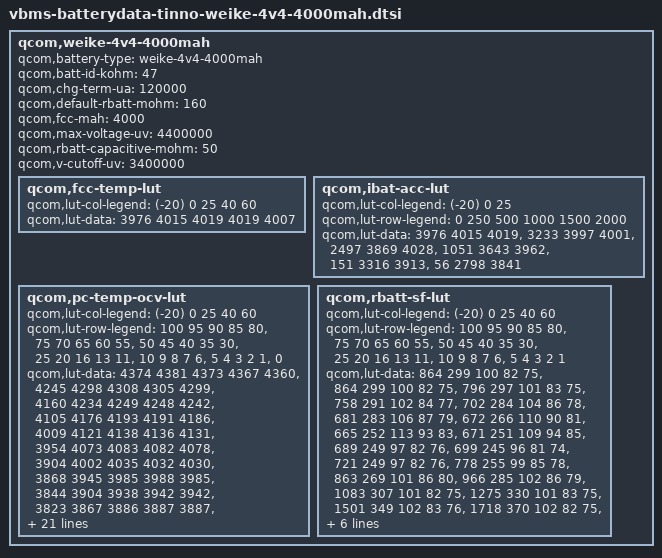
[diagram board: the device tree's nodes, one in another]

qcom,weike-4v4-4000mah {
	qcom,battery-type = "weike-4v4-4000mah";
	qcom,batt-id-kohm = <47>;
	qcom,chg-term-ua = <120000>;
	qcom,default-rbatt-mohm = <160>;
	qcom,fcc-mah = <4000>;
	qcom,max-voltage-uv = <4400000>;
	qcom,rbatt-capacitive-mohm = <50>;
	qcom,v-cutoff-uv = <3400000>;

	qcom,fcc-temp-lut {
		qcom,lut-col-legend = <(-20) 0 25 40 60>;
		qcom,lut-data = <3976 4015 4019 4019 4007>;
	};

	qcom,ibat-acc-lut {
		qcom,lut-col-legend = <(-20) 0 25>;
		qcom,lut-row-legend = <0 250 500 1000 1500 2000>;
		qcom,lut-data = <3976 4015 4019>,
				<3233 3997 4001>,
				<2497 3869 4028>,
				<1051 3643 3962>,
				<151 3316 3913>,
				<56 2798 3841>;
	};

	qcom,pc-temp-ocv-lut {
		qcom,lut-col-legend = <(-20) 0 25 40 60>;
		qcom,lut-row-legend = <100 95 90 85 80>,
					<75 70 65 60 55>,
					<50 45 40 35 30>,
					<25 20 16 13 11>,
					<10 9 8 7 6>,
					<5 4 3 2 1>,
					<0>;
		qcom,lut-data = <4374 4381 4373 4367 4360>,
				<4245 4298 4308 4305 4299>,
				<4160 4234 4249 4248 4242>,
				<4105 4176 4193 4191 4186>,
				<4009 4121 4138 4136 4131>,
				<3954 4073 4083 4082 4078>,
				<3904 4002 4035 4032 4030>,
				<3868 3945 3985 3988 3985>,
				<3844 3904 3938 3942 3942>,
				<3823 3867 3886 3887 3887>,
				<3806 3834 3852 3853 3853>,
				<3789 3809 3826 3828 3827>,
				<3773 3793 3805 3807 3806>,
				<3758 3780 3787 3788 3788>,
				<3744 3768 3772 3771 3767>,
				<3728 3754 3756 3749 3738>,
				<3709 3734 3738 3729 3716>,
				<3690 3715 3717 3708 3696>,
				<3674 3703 3697 3689 3677>,
				<3660 3695 3687 3681 3670>,
				<3654 3690 3685 3679 3669>,
				<3645 3686 3684 3678 3667>,
				<3632 3681 3682 3676 3665>,
				<3618 3675 3679 3673 3662>,
				<3600 3664 3670 3663 3651>,
				<3577 3640 3646 3637 3621>,
				<3546 3599 3601 3590 3573>,
				<3499 3538 3538 3527 3510>,
				<3428 3449 3451 3437 3422>,
				<3300 3306 3306 3289 3280>,
				<3075 3065 3050 3044 3000>;
	};

	qcom,rbatt-sf-lut {
		qcom,lut-col-legend = <(-20) 0 25 40 60>;
		qcom,lut-row-legend = <100 95 90 85 80>,
					<75 70 65 60 55>,
					<50 45 40 35 30>,
					<25 20 16 13 11>,
					<10 9 8 7 6>,
					<5 4 3 2 1>;
		qcom,lut-data = <864 299 100 82 75>,
				<864 299 100 82 75>,
				<796 297 101 83 75>,
				<758 291 102 84 77>,
				<702 284 104 86 78>,
				<681 283 106 87 79>,
				<672 266 110 90 81>,
				<665 252 113 93 83>,
				<671 251 109 94 85>,
				<689 249 97 82 76>,
				<699 245 96 81 74>,
				<721 249 97 82 76>,
				<778 255 99 85 78>,
				<863 269 101 86 80>,
				<966 285 102 86 79>,
				<1083 307 101 82 75>,
				<1275 330 101 83 75>,
				<1501 349 102 83 76>,
				<1718 370 102 82 75>,
				<1878 378 102 82 75>,
				<1872 373 102 83 76>,
				<1900 385 104 84 77>,
				<2075 400 107 86 79>,
				<2289 415 110 89 82>,
				<2563 430 112 90 82>,
				<2864 442 110 87 77>,
				<3282 459 109 84 77>,
				<3977 492 113 86 78>,
				<5073 578 119 89 80>,
				<7786 1155 151 116 160>;
	};
};
